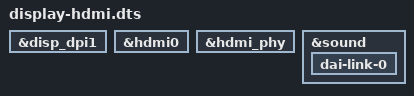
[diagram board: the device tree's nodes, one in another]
// SPDX-License-Identifier: GPL-2.0
/*
 * Copyright (C) 2024 MediaTek Inc.
 * Copyright (C) 2026 Grinn sp. z o.o.
 */

/dts-v1/;
/plugin/;

/ {
	fragment@0 {
		target = <&disp_dpi1>;

		__overlay__ {
			status = "okay";
		};
	};

	fragment@1 {
		target = <&hdmi0>;

		__overlay__ {
			status = "okay";
		};
	};

	fragment@2 {
		target = <&hdmi_phy>;

		__overlay__ {
			status = "okay";
		};
	};

	fragment@3 {
		target = <&sound>;

		__overlay__ {
			dai-link-0 {
				status = "okay";
			};
		};
	};
};
